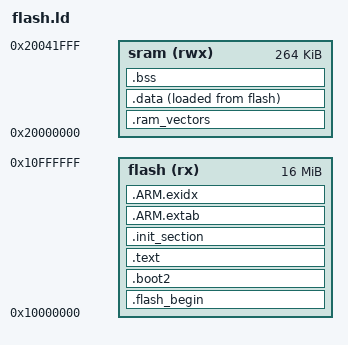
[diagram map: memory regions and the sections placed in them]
MEMORY
{
    /* OpenFC2040 uses W25Q128JV (128Mbit = 16MB)
     * ORIGIN: 0x10000000 (XIP Base)
     * LENGTH: 16384K (16MB)
     */
    flash (rx) : ORIGIN = 0x10000000, LENGTH = 16384K
    
    /* RP2040 SRAM (264KB) */
    sram (rwx) : ORIGIN = 0x20000000, LENGTH = 264K
}

OUTPUT_ARCH(arm)
EXTERN(_vectors)
ENTRY(_stext)
EXTERN(bootStr)

SECTIONS
{
    .flash_begin : {
        __flash_binary_start = .;
    } > flash

    .boot2 : {
        __boot2_start__ = .;
        KEEP (*(.boot2))
        __boot2_end__ = .;
    } > flash

    .text : {
        _stext = ABSOLUTE(.);
        *(.vectors)
        *(.text .text.*)
        *(.fixup)
        *(.gnu.warning)
        *(.rodata .rodata.*)
        *(.gnu.linkonce.t.*)
        *(.glue_7)
        *(.glue_7t)
        *(.got)
        *(.gcc_except_table)
        *(.gnu.linkonce.r.*)
        _etext = ABSOLUTE(.);
    } > flash

    .init_section : {
        _sinit = ABSOLUTE(.);
        KEEP (*(.init_array .init_array.*))
        _einit = ABSOLUTE(.);
    } > flash

    .ARM.extab : {
        *(.ARM.extab*)
    } > flash

    __exidx_start = ABSOLUTE(.);
    .ARM.exidx : {
        *(.ARM.exidx*)
    } > flash
    __exidx_end = ABSOLUTE(.);

    _eronly = ABSOLUTE(.);

    .ram_vectors (COPY) : {
        *(.ram_vectors)
    } > sram

    .data : {
        _sdata = ABSOLUTE(.);
        *(.data .data.*)
        *(.gnu.linkonce.d.*)
        CONSTRUCTORS
        . = ALIGN(4);
        _edata = ABSOLUTE(.);
    } > sram AT > flash

    .bss : {
        _sbss = ABSOLUTE(.);
        *(.bss .bss.*)
        *(.gnu.linkonce.b.*)
        *(COMMON)
        . = ALIGN(4);
        _ebss = ABSOLUTE(.);
    } > sram

    /* Stabs debugging sections. */
    .stab 0 : { *(.stab) }
    .stabstr 0 : { *(.stabstr) }
    .stab.excl 0 : { *(.stab.excl) }
    .stab.exclstr 0 : { *(.stab.exclstr) }
    .stab.index 0 : { *(.stab.index) }
    .stab.indexstr 0 : { *(.stab.indexstr) }
    .comment 0 : { *(.comment) }
    .debug_abbrev 0 : { *(.debug_abbrev) }
    .debug_info 0 : { *(.debug_info) }
    .debug_line 0 : { *(.debug_line) }
    .debug_pubnames 0 : { *(.debug_pubnames) }
    .debug_aranges 0 : { *(.debug_aranges) }
}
